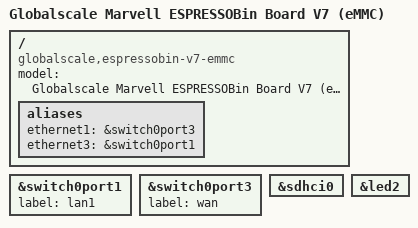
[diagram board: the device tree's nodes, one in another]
/dts-v1/;
#include "armada-3720-espressobin.dtsi"
/ {
	model = "Globalscale Marvell ESPRESSOBin Board V7 (eMMC)";
	compatible = "globalscale,espressobin-v7-emmc", "globalscale,espressobin-v7",
		     "globalscale,espressobin", "marvell,armada3720",
		     "marvell,armada3700";
	aliases {
		ethernet1 = &switch0port3;
		ethernet3 = &switch0port1;
	};
};
&switch0port1 {
	label = "lan1";
};
&switch0port3 {
	label = "wan";
};
&sdhci0 {
	status = "okay";
};
&led2 {
	status = "okay";
};
